AUTOSAR XML (schema 00044)
package /ComponentTypes
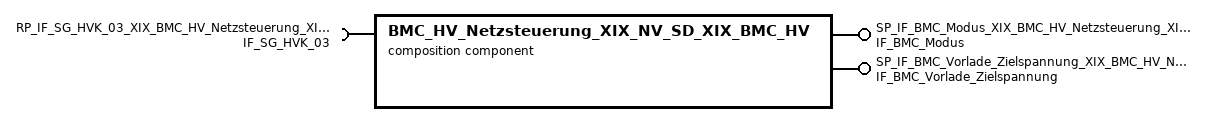
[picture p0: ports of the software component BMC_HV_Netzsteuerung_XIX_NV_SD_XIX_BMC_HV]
  composition sw component type BMC_HV_Netzsteuerung_XIX_NV_SD_XIX_BMC_HV
    provide port SP_IF_BMC_Modus_XIX_BMC_HV_Netzsteuerung_XIX_NV_SD_XIX_BMC_HV: nonqueued-sender-com-spec=DE_BMC_Modus, provided-interface=IF_BMC_Modus
    provide port SP_IF_BMC_Vorlade_Zielspannung_XIX_BMC_HV_Netzsteuerung_XIX_NV_SD_XIX_BMC_HV: nonqueued-sender-com-spec=DE_BMC_Vorlade_Zielspannung, provided-interface=IF_BMC_Vorlade_Zielspannung
    require port RP_IF_SG_HVK_03_XIX_BMC_HV_Netzsteuerung_XIX_NV_SD_XIX_BMC_HV: nonqueued-receiver-com-spec=DE_SG_HVK_03, required-interface=IF_SG_HVK_03
